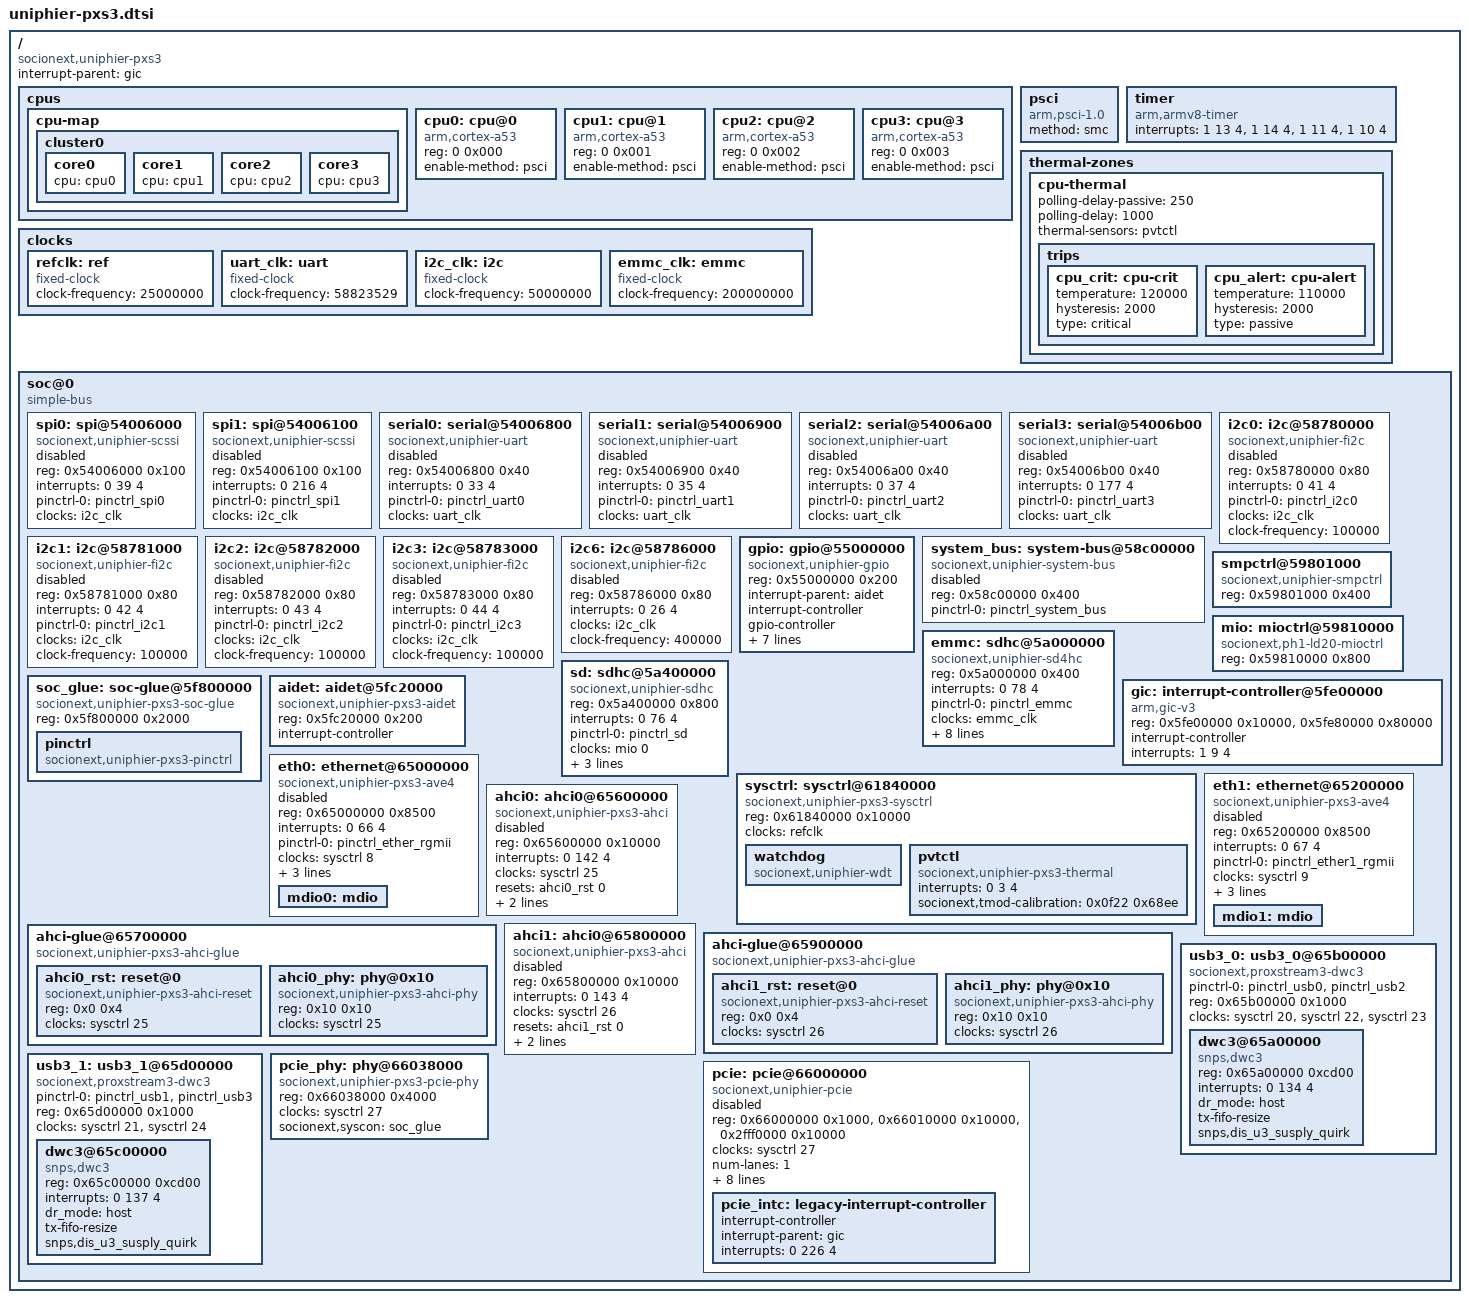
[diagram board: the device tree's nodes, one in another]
/*
 * Device Tree Source for UniPhier PXs3 SoC
 *
 * Copyright (C) 2017 Socionext Inc.
 *   Author: Masahiro Yamada <yamada.masahiro@socionext.com>
 *
 * SPDX-License-Identifier: (GPL-2.0+ OR MIT)
 */

#include <dt-bindings/gpio/gpio.h>
#include <dt-bindings/gpio/uniphier-gpio.h>

/memreserve/ 0x80000000 0x02000000;

/ {
	compatible = "socionext,uniphier-pxs3";
	#address-cells = <2>;
	#size-cells = <2>;
	interrupt-parent = <&gic>;

	cpus {
		#address-cells = <2>;
		#size-cells = <0>;

		cpu-map {
			cluster0 {
				core0 {
					cpu = <&cpu0>;
				};
				core1 {
					cpu = <&cpu1>;
				};
				core2 {
					cpu = <&cpu2>;
				};
				core3 {
					cpu = <&cpu3>;
				};
			};
		};

		cpu0: cpu@0 {
			device_type = "cpu";
			compatible = "arm,cortex-a53", "arm,armv8";
			reg = <0 0x000>;
			enable-method = "psci";
		};

		cpu1: cpu@1 {
			device_type = "cpu";
			compatible = "arm,cortex-a53", "arm,armv8";
			reg = <0 0x001>;
			enable-method = "psci";
		};

		cpu2: cpu@2 {
			device_type = "cpu";
			compatible = "arm,cortex-a53", "arm,armv8";
			reg = <0 0x002>;
			enable-method = "psci";
		};

		cpu3: cpu@3 {
			device_type = "cpu";
			compatible = "arm,cortex-a53", "arm,armv8";
			reg = <0 0x003>;
			enable-method = "psci";
		};
	};

	psci {
		compatible = "arm,psci-1.0";
		method = "smc";
	};

	clocks {
		refclk: ref {
			compatible = "fixed-clock";
			#clock-cells = <0>;
			clock-frequency = <25000000>;
		};

		uart_clk: uart {
			compatible = "fixed-clock";
			#clock-cells = <0>;
			clock-frequency = <58823529>;
		};

		i2c_clk: i2c {
			compatible = "fixed-clock";
			#clock-cells = <0>;
			clock-frequency = <50000000>;
		};

		emmc_clk: emmc {
			compatible = "fixed-clock";
			#clock-cells = <0>;
			clock-frequency = <200000000>;
		};
	};

	timer {
		compatible = "arm,armv8-timer";
		interrupts = <1 13 4>,
			     <1 14 4>,
			     <1 11 4>,
			     <1 10 4>;
	};

	thermal-zones {
		cpu-thermal {
			polling-delay-passive = <250>;	/* 250ms */
			polling-delay = <1000>;		/* 1000ms */
			thermal-sensors = <&pvtctl>;

			trips {
				cpu_crit: cpu-crit {
					temperature = <120000>;	/* 120C */
					hysteresis = <2000>;
					type = "critical";
				};
				cpu_alert: cpu-alert {
					temperature = <110000>;	/* 110C */
					hysteresis = <2000>;
					type = "passive";
				};
			};
		};
	};

	soc@0 {
		compatible = "simple-bus";
		#address-cells = <1>;
		#size-cells = <1>;
		ranges = <0 0 0 0xffffffff>;

		spi0: spi@54006000 {
			compatible = "socionext,uniphier-scssi";
			status = "disabled";
			reg = <0x54006000 0x100>;
			interrupts = <0 39 4>;
			pinctrl-names = "default";
			pinctrl-0 = <&pinctrl_spi0>;
			clocks = <&i2c_clk>;
		};

		spi1: spi@54006100 {
			compatible = "socionext,uniphier-scssi";
			status = "disabled";
			reg = <0x54006100 0x100>;
			interrupts = <0 216 4>;
			pinctrl-names = "default";
			pinctrl-0 = <&pinctrl_spi1>;
			clocks = <&i2c_clk>;
		};

		serial0: serial@54006800 {
			compatible = "socionext,uniphier-uart";
			status = "disabled";
			reg = <0x54006800 0x40>;
			interrupts = <0 33 4>;
			pinctrl-names = "default";
			pinctrl-0 = <&pinctrl_uart0>;
			clocks = <&uart_clk>;
		};

		serial1: serial@54006900 {
			compatible = "socionext,uniphier-uart";
			status = "disabled";
			reg = <0x54006900 0x40>;
			interrupts = <0 35 4>;
			pinctrl-names = "default";
			pinctrl-0 = <&pinctrl_uart1>;
			clocks = <&uart_clk>;
		};

		serial2: serial@54006a00 {
			compatible = "socionext,uniphier-uart";
			status = "disabled";
			reg = <0x54006a00 0x40>;
			interrupts = <0 37 4>;
			pinctrl-names = "default";
			pinctrl-0 = <&pinctrl_uart2>;
			clocks = <&uart_clk>;
		};

		serial3: serial@54006b00 {
			compatible = "socionext,uniphier-uart";
			status = "disabled";
			reg = <0x54006b00 0x40>;
			interrupts = <0 177 4>;
			pinctrl-names = "default";
			pinctrl-0 = <&pinctrl_uart3>;
			clocks = <&uart_clk>;
		};

		i2c0: i2c@58780000 {
			compatible = "socionext,uniphier-fi2c";
			status = "disabled";
			reg = <0x58780000 0x80>;
			#address-cells = <1>;
			#size-cells = <0>;
			interrupts = <0 41 4>;
			pinctrl-names = "default";
			pinctrl-0 = <&pinctrl_i2c0>;
			clocks = <&i2c_clk>;
			clock-frequency = <100000>;
		};

		i2c1: i2c@58781000 {
			compatible = "socionext,uniphier-fi2c";
			status = "disabled";
			reg = <0x58781000 0x80>;
			#address-cells = <1>;
			#size-cells = <0>;
			interrupts = <0 42 4>;
			pinctrl-names = "default";
			pinctrl-0 = <&pinctrl_i2c1>;
			clocks = <&i2c_clk>;
			clock-frequency = <100000>;
		};

		i2c2: i2c@58782000 {
			compatible = "socionext,uniphier-fi2c";
			status = "disabled";
			reg = <0x58782000 0x80>;
			#address-cells = <1>;
			#size-cells = <0>;
			interrupts = <0 43 4>;
			pinctrl-names = "default";
			pinctrl-0 = <&pinctrl_i2c2>;
			clocks = <&i2c_clk>;
			clock-frequency = <100000>;
		};

		i2c3: i2c@58783000 {
			compatible = "socionext,uniphier-fi2c";
			status = "disabled";
			reg = <0x58783000 0x80>;
			#address-cells = <1>;
			#size-cells = <0>;
			interrupts = <0 44 4>;
			pinctrl-names = "default";
			pinctrl-0 = <&pinctrl_i2c3>;
			clocks = <&i2c_clk>;
			clock-frequency = <100000>;
		};

		/* chip-internal connection for HDMI */
		i2c6: i2c@58786000 {
			compatible = "socionext,uniphier-fi2c";
			status = "disabled";
			reg = <0x58786000 0x80>;
			#address-cells = <1>;
			#size-cells = <0>;
			interrupts = <0 26 4>;
			clocks = <&i2c_clk>;
			clock-frequency = <400000>;
		};

		gpio: gpio@55000000 {
			compatible = "socionext,uniphier-gpio";
			reg = <0x55000000 0x200>;
			interrupt-parent = <&aidet>;
			interrupt-controller;
			#interrupt-cells = <2>;
			gpio-controller;
			#gpio-cells = <2>;
			gpio-ranges = <&pinctrl 0 0 0>,
				      <&pinctrl 104 0 0>,
				      <&pinctrl 168 0 0>;
			gpio-ranges-group-names = "gpio_range0",
						  "gpio_range1",
						  "gpio_range2";
			ngpios = <286>;
			socionext,interrupt-ranges = <0 48 16>, <16 154 5>,
						     <21 217 3>;
		};

		system_bus: system-bus@58c00000 {
			compatible = "socionext,uniphier-system-bus";
			status = "disabled";
			reg = <0x58c00000 0x400>;
			#address-cells = <2>;
			#size-cells = <1>;
			pinctrl-names = "default";
			pinctrl-0 = <&pinctrl_system_bus>;
		};

		smpctrl@59801000 {
			compatible = "socionext,uniphier-smpctrl";
			reg = <0x59801000 0x400>;
		};

		mio: mioctrl@59810000 {
			compatible = "socionext,ph1-ld20-mioctrl";
			reg = <0x59810000 0x800>;
			#clock-cells = <1>;
		};

		emmc: sdhc@5a000000 {
			compatible = "socionext,uniphier-sd4hc", "cdns,sd4hc";
			reg = <0x5a000000 0x400>;
			interrupts = <0 78 4>;
			pinctrl-names = "default";
			pinctrl-0 = <&pinctrl_emmc>;
			clocks = <&emmc_clk>;
			bus-width = <8>;
			mmc-ddr-1_8v;
			mmc-hs200-1_8v;
			cdns,phy-input-delay-legacy = <4>;
			cdns,phy-input-delay-mmc-highspeed = <2>;
			cdns,phy-input-delay-mmc-ddr = <3>;
			cdns,phy-dll-delay-sdclk = <21>;
			cdns,phy-dll-delay-sdclk-hsmmc = <21>;
		};

		sd: sdhc@5a400000 {
			compatible = "socionext,uniphier-sdhc";
			reg = <0x5a400000 0x800>;
			interrupts = <0 76 4>;
			pinctrl-names = "default";
			pinctrl-0 = <&pinctrl_sd>;
			clocks = <&mio 0>;
			bus-width = <4>;
			no-1-8-v;
			cap-sd-highspeed;
		};

		soc_glue: soc-glue@5f800000 {
			compatible = "socionext,uniphier-pxs3-soc-glue",
				     "simple-mfd", "syscon";
			reg = <0x5f800000 0x2000>;

			pinctrl: pinctrl {
				compatible = "socionext,uniphier-pxs3-pinctrl";
			};
		};

		aidet: aidet@5fc20000 {
			compatible = "socionext,uniphier-pxs3-aidet";
			reg = <0x5fc20000 0x200>;
			interrupt-controller;
			#interrupt-cells = <2>;
		};

		gic: interrupt-controller@5fe00000 {
			compatible = "arm,gic-v3";
			reg = <0x5fe00000 0x10000>,	/* GICD */
			      <0x5fe80000 0x80000>;	/* GICR */
			interrupt-controller;
			#interrupt-cells = <3>;
			interrupts = <1 9 4>;
		};

		sysctrl: sysctrl@61840000 {
			compatible = "socionext,uniphier-pxs3-sysctrl",
				     "simple-mfd", "syscon";
			reg = <0x61840000 0x10000>;
			#clock-cells = <1>;
			clock-names = "ref";
			clocks = <&refclk>;

			watchdog {
				compatible = "socionext,uniphier-wdt";
			};

			pvtctl: pvtctl {
				compatible = "socionext,uniphier-pxs3-thermal";
				interrupts = <0 3 4>;
				#thermal-sensor-cells = <0>;
				socionext,tmod-calibration = <0x0f22 0x68ee>;
			};
		};

		eth0: ethernet@65000000 {
			compatible = "socionext,uniphier-pxs3-ave4";
			status = "disabled";
			reg = <0x65000000 0x8500>;
			interrupts = <0 66 4>;
			pinctrl-names = "default";
			pinctrl-0 = <&pinctrl_ether_rgmii>;
			clock-names = "ether";
			clocks = <&sysctrl 8>;
			phy-mode = "rgmii";
			local-mac-address = [00 00 00 00 00 00];
			socionext,syscon-phy-mode = <&soc_glue 0>;

			mdio0: mdio {
				#address-cells = <1>;
				#size-cells = <0>;
			};
		};

		eth1: ethernet@65200000 {
			compatible = "socionext,uniphier-pxs3-ave4";
			status = "disabled";
			reg = <0x65200000 0x8500>;
			interrupts = <0 67 4>;
			pinctrl-names = "default";
			pinctrl-0 = <&pinctrl_ether1_rgmii>;
			clock-names = "ether";
			clocks = <&sysctrl 9>;
			phy-mode = "rgmii";
			local-mac-address = [00 00 00 00 00 00];
			socionext,syscon-phy-mode = <&soc_glue 1>;

			mdio1: mdio {
				#address-cells = <1>;
				#size-cells = <0>;
			};
		};

		ahci0: ahci0@65600000 {
			compatible = "socionext,uniphier-pxs3-ahci",
				     "generic-ahci";
			status = "disabled";
			reg = <0x65600000 0x10000>;
			interrupts = <0 142 4>;
			clocks = <&sysctrl 25>;
			resets = <&ahci0_rst 0>;
			ports-implemented = <1>;
			phys = <&ahci0_phy>;
		};

		ahci-glue@65700000 {
			compatible = "socionext,uniphier-pxs3-ahci-glue",
				     "simple-mfd";
			#address-cells = <1>;
			#size-cells = <1>;
			ranges = <0 0x65700000 0x100>;

			ahci0_rst: reset@0 {
				compatible = "socionext,uniphier-pxs3-ahci-reset";
				reg = <0x0 0x4>;
				clock-names = "link";
				clocks = <&sysctrl 25>;
				#reset-cells = <1>;
			};

			ahci0_phy: phy@0x10 {
				compatible = "socionext,uniphier-pxs3-ahci-phy";
				reg = <0x10 0x10>;
				clock-names = "link";
				clocks = <&sysctrl 25>;
				#phy-cells = <0>;
			};
		};

		ahci1: ahci0@65800000 {
			compatible = "socionext,uniphier-pxs3-ahci",
				     "generic-ahci";
			status = "disabled";
			reg = <0x65800000 0x10000>;
			interrupts = <0 143 4>;
			clocks = <&sysctrl 26>;
			resets = <&ahci1_rst 0>;
			ports-implemented = <1>;
			phys = <&ahci1_phy>;
		};

		ahci-glue@65900000 {
			compatible = "socionext,uniphier-pxs3-ahci-glue",
				     "simple-mfd";
			#address-cells = <1>;
			#size-cells = <1>;
			ranges = <0 0x65900000 0x100>;

			ahci1_rst: reset@0 {
				compatible = "socionext,uniphier-pxs3-ahci-reset";
				reg = <0x0 0x4>;
				clock-names = "link";
				clocks = <&sysctrl 26>;
				#reset-cells = <1>;
			};

			ahci1_phy: phy@0x10 {
				compatible = "socionext,uniphier-pxs3-ahci-phy";
				reg = <0x10 0x10>;
				clock-names = "link";
				clocks = <&sysctrl 26>;
				#phy-cells = <0>;
			};
		};

		usb3_0: usb3_0@65b00000 {
			compatible = "socionext,proxstream3-dwc3";
			pinctrl-names = "default";
			pinctrl-0 = <&pinctrl_usb0>, <&pinctrl_usb2>;
			reg = <0x65b00000 0x1000>;
			clocks = <&sysctrl 20>, <&sysctrl 22>, <&sysctrl 23>;
			clock-names = "u3clk0", "u3clk1", "u2clk0";
			#address-cells = <1>;
			#size-cells = <1>;
			ranges;
			dwc3@65a00000 {
				compatible = "snps,dwc3";
				reg = <0x65a00000 0xcd00>;
				interrupts = <0 134 4>;
				dr_mode = "host";
				tx-fifo-resize;
				snps,dis_u3_susply_quirk;
			};
		};

		usb3_1: usb3_1@65d00000 {
			compatible = "socionext,proxstream3-dwc3";
			pinctrl-names = "default";
			pinctrl-0 = <&pinctrl_usb1>, <&pinctrl_usb3>;
			reg = <0x65d00000 0x1000>;
			clocks = <&sysctrl 21>, <&sysctrl 24>;
			clock-names = "u3clk0", "u2clk0";
			#address-cells = <1>;
			#size-cells = <1>;
			ranges;
			dwc3@65c00000 {
				compatible = "snps,dwc3";
				reg = <0x65c00000 0xcd00>;
				interrupts = <0 137 4>;
				dr_mode = "host";
				tx-fifo-resize;
				snps,dis_u3_susply_quirk;
			};
		};

		pcie: pcie@66000000 {
			compatible = "socionext,uniphier-pcie", "snps,dw-pcie";
			status = "disabled";
			reg-names = "dbi", "link", "config";
			reg = <0x66000000 0x1000>, <0x66010000 0x10000>,
			      <0x2fff0000 0x10000>;
			#address-cells = <3>;
			#size-cells = <2>;
			clocks = <&sysctrl 27>;
			num-lanes = <1>;
			num-viewport = <1>;
			bus-range = <0x0 0xff>;
			device_type = "pci";
			ranges =
			/* downstream I/O */
				<0x81000000 0 0x00000000  0x2ffe0000  0 0x00010000
			/* non-prefetchable memory */
				 0x82000000 0 0x20000000  0x20000000  0 0x0ffe0000>;
			#interrupt-cells = <1>;
			interrupt-names = "dma", "msi";
			interrupts = <0 224 4>, <0 225 4>;
			interrupt-map-mask = <0 0 0  7>;
			interrupt-map = <0 0 0  1  &pcie_intc 0>,	/* INTA */
					<0 0 0  2  &pcie_intc 1>,	/* INTB */
					<0 0 0  3  &pcie_intc 2>,	/* INTC */
					<0 0 0  4  &pcie_intc 3>;	/* INTD */
			phy-names = "pcie-phy";
			phys = <&pcie_phy>;

			pcie_intc: legacy-interrupt-controller {
				interrupt-controller;
				#interrupt-cells = <1>;
				interrupt-parent = <&gic>;
				interrupts = <0 226 4>;
			};
		};

		pcie_phy: phy@66038000 {
			compatible = "socionext,uniphier-pxs3-pcie-phy";
			reg = <0x66038000 0x4000>;
			#phy-cells = <0>;
			clocks = <&sysctrl 27>;
			socionext,syscon = <&soc_glue>;
		};
	};
};

#include "uniphier-pinctrl.dtsi"
